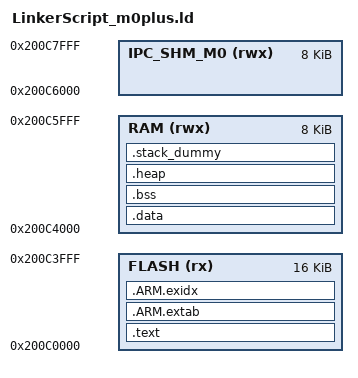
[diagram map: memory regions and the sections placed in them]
/* Linker script to configure memory regions. */
/* For CM0+, the memory mapping of the LPSRAM must necessarily be defined between 0x200C0000 and 0x200C7FFF */
MEMORY
{
  FLASH        (rx)  : ORIGIN = 0x200C0000, LENGTH = 16K /* 0x200C0000 -> 0x200C3FFF : LPSRAM1(8K)/LPSRAM2(8K) */
  RAM          (rwx) : ORIGIN = 0x200C4000, LENGTH = 8K  /* 0x200C4000 -> 0x200C5FFF : LPSRAM3(8K) */
  IPC_SHM_M0   (rwx) : ORIGIN = 0x200C6000, LENGTH = 8K  /* 0x200C6000 -> 0x200C7FFF : LPSRAM3(8K)*/
}

/* Symbols needed for IPCC communication */
__IPC_SHM_region_start__   = ORIGIN(IPC_SHM_M0);
__IPC_SHM_region_length__  = LENGTH(IPC_SHM_M0);

/* Library configurations */
GROUP(libgcc.a libc.a libm.a libnosys.a)

/* Linker script to place sections and symbol values. Should be used together
 * with other linker script that defines memory regions FLASH and RAM.
 * It references following symbols, which must be defined in code:
 *   Reset_Handler : Entry of reset handler
 *
 * It defines following symbols, which code can use without definition:
 *   __exidx_start
 *   __exidx_end
 *   __copy_table_start__
 *   __copy_table_end__
 *   __zero_table_start__
 *   __zero_table_end__
 *   __etext
 *   __data_start__
 *   __preinit_array_start
 *   __preinit_array_end
 *   __init_array_start
 *   __init_array_end
 *   __fini_array_start
 *   __fini_array_end
 *   __data_end__
 *   __bss_start__
 *   __bss_end__
 *   __end__
 *   end
 *   __HeapBase
 *   __HeapLimit
 *   __StackLimit
 *   __StackTop
 *   __stack
 *   __Vectors_End
 *   __Vectors_Size
 */
ENTRY(Reset_Handler)

SECTIONS
{
    .text :
    {
        KEEP(*(.isr_vector))
        __Vectors_End = .;
        __Vectors_Size = __Vectors_End - g_pfnVectors;
        __end__ = .;

        *(.text*)

        KEEP(*(.init))
        KEEP(*(.fini))

        /* .ctors */
        *crtbegin.o(.ctors)
        *crtbegin?.o(.ctors)
        *(EXCLUDE_FILE(*crtend?.o *crtend.o) .ctors)
        *(SORT(.ctors.*))
        *(.ctors)

        /* .dtors */
        *crtbegin.o(.dtors)
        *crtbegin?.o(.dtors)
        *(EXCLUDE_FILE(*crtend?.o *crtend.o) .dtors)
        *(SORT(.dtors.*))
        *(.dtors)

        *(.rodata*)

        KEEP(*(.eh_frame*))
    } > FLASH

    .ARM.extab :
    {
        *(.ARM.extab* .gnu.linkonce.armextab.*)
    } > FLASH

    __exidx_start = .;
    .ARM.exidx :
    {
        *(.ARM.exidx* .gnu.linkonce.armexidx.*)
    } > FLASH
    __exidx_end = .;

    /* To copy multiple ROM to RAM sections,
     * uncomment .copy.table section and,
     * define __STARTUP_COPY_MULTIPLE in startup_ARMCMx.S */
    /*
    .copy.table :
    {
        . = ALIGN(4);
        __copy_table_start__ = .;
        LONG (__etext)
        LONG (__data_start__)
        LONG (__data_end__ - __data_start__)
        LONG (__etext2)
        LONG (__data2_start__)
        LONG (__data2_end__ - __data2_start__)
        __copy_table_end__ = .;
    } > FLASH
    */

    /* To clear multiple BSS sections,
     * uncomment .zero.table section and,
     * define __STARTUP_CLEAR_BSS_MULTIPLE in startup_ARMCMx.S */
    /*
    .zero.table :
    {
        . = ALIGN(4);
        __zero_table_start__ = .;
        LONG (__bss_start__)
        LONG (__bss_end__ - __bss_start__)
        LONG (__bss2_start__)
        LONG (__bss2_end__ - __bss2_start__)
        __zero_table_end__ = .;
    } > FLASH
    */

  /* used by the startup to initialize data */
  _sidata = LOADADDR(.data);

  __etext = .;

    .data : AT (__etext)
    {
        /* create a global symbol at data start */
        _sdata = .;
        *(vtable)
        *(.data*)

        . = ALIGN(4);
        /* preinit data */
        PROVIDE_HIDDEN (__preinit_array_start = .);
        KEEP(*(.preinit_array))
        PROVIDE_HIDDEN (__preinit_array_end = .);

        . = ALIGN(4);
        /* init data */
        PROVIDE_HIDDEN (__init_array_start = .);
        KEEP(*(SORT(.init_array.*)))
        KEEP(*(.init_array))
        PROVIDE_HIDDEN (__init_array_end = .);


        . = ALIGN(4);
        /* finit data */
        PROVIDE_HIDDEN (__fini_array_start = .);
        KEEP(*(SORT(.fini_array.*)))
        KEEP(*(.fini_array))
        PROVIDE_HIDDEN (__fini_array_end = .);

        KEEP(*(.jcr*))
        . = ALIGN(4);
        /* define a global symbol at data end */
        _edata = .;
    } > RAM

    .bss :
    {
        . = ALIGN(4);
        /* This is used by the startup in order to initialize the .bss section */
        /* define a global symbol at bss start */
        _sbss = .;
        __bss_start__ = _sbss;
        *(.bss*)
        *(COMMON)
        . = ALIGN(4);
        /* define a global symbol at bss end */
        _ebss = .;
        __bss_end__ = _ebss;
    } > RAM

    .heap (COPY):
    {
        __HeapBase = .;
        __end__ = .;
        end = __end__;
        KEEP(*(.heap*))
        __HeapLimit = .;
    } > RAM

    /* .stack_dummy section doesn't contains any symbols. It is only
     * used for linker to calculate size of stack sections, and assign
     * values to stack symbols later */
    .stack_dummy (COPY):
    {
        KEEP(*(.stack*))
    } > RAM

    /* Set stack top to end of RAM, and stack limit move down by
     * size of stack_dummy section */
    __StackTop = ORIGIN(RAM) + LENGTH(RAM);
	/* Highest address of the user mode stack */
    _estack = __StackTop;
    __StackLimit = __StackTop - SIZEOF(.stack_dummy);
    PROVIDE(__stack = __StackTop);

    /* Check if data + heap + stack exceeds RAM limit */
    ASSERT(__StackLimit >= __HeapLimit, "region RAM overflowed with stack")
}
